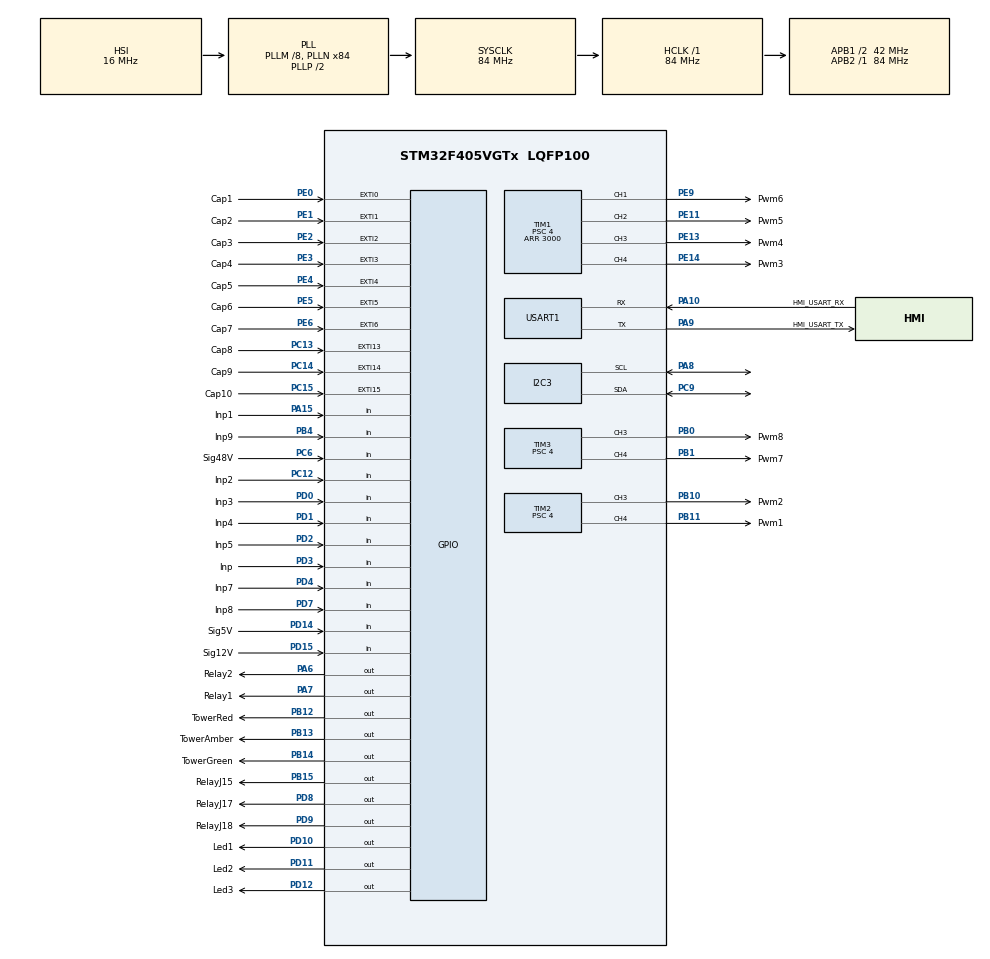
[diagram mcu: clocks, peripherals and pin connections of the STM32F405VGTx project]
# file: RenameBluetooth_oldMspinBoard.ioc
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Mcu.Family=STM32F4
Mcu.Name=STM32F405VGTx
Mcu.Package=LQFP100
NVIC.EXTI0_IRQn=true\:0\:0\:false\:false\:true\:true\:true\:true
NVIC.EXTI15_10_IRQn=true\:0\:0\:false\:false\:true\:true\:true\:true
NVIC.EXTI1_IRQn=true\:0\:0\:false\:false\:true\:true\:true\:true
NVIC.EXTI2_IRQn=true\:0\:0\:false\:false\:true\:true\:true\:true
NVIC.EXTI3_IRQn=true\:0\:0\:false\:false\:true\:true\:true\:true
NVIC.EXTI4_IRQn=true\:0\:0\:false\:false\:true\:true\:true\:true
NVIC.EXTI9_5_IRQn=true\:0\:0\:false\:false\:true\:true\:true\:true
NVIC.PriorityGroup=NVIC_PRIORITYGROUP_4
NVIC.TIM6_DAC_IRQn=true\:0\:0\:false\:false\:true\:true\:true\:true
NVIC.TIM7_IRQn=true\:0\:0\:false\:false\:true\:true\:true\:true
NVIC.USART1_IRQn=true\:0\:0\:false\:false\:true\:true\:true\:true
PA10.GPIO_Label=HMI_USART_RX
PA10.Mode=Asynchronous
PA10.Signal=USART1_RX
PA15.GPIO_Label=Inp1
PA15.Signal=GPIO_Input
PA6.GPIO_Label=Relay2
PA6.Signal=GPIO_Output
PA7.GPIO_Label=Relay1
PA7.Signal=GPIO_Output
PA8.GPIO_Pu=GPIO_PULLUP
PA8.Mode=I2C
PA8.Signal=I2C3_SCL
PA9.GPIO_Label=HMI_USART_TX
PA9.Mode=Asynchronous
PA9.Signal=USART1_TX
PB0.GPIO_Label=Pwm8
PB0.Signal=S_TIM3_CH3
PB1.GPIO_Label=Pwm7
PB1.Signal=S_TIM3_CH4
PB10.GPIO_Label=Pwm2
PB10.Signal=S_TIM2_CH3
PB11.GPIO_Label=Pwm1
PB11.Signal=S_TIM2_CH4
PB12.GPIO_Label=TowerRed
PB12.Signal=GPIO_Output
PB13.GPIO_Label=TowerAmber
PB13.Signal=GPIO_Output
PB14.GPIO_Label=TowerGreen
PB14.Signal=GPIO_Output
PB15.GPIO_Label=RelayJ15
PB15.Signal=GPIO_Output
PB4.GPIO_Label=Inp9
PB4.Signal=GPIO_Input
PC12.GPIO_Label=Inp2
PC12.Signal=GPIO_Input
PC13-ANTI_TAMP.GPIO_Label=Cap8
PC13-ANTI_TAMP.GPIO_ModeDefaultEXTI=GPIO_MODE_IT_RISING_FALLING
PC13-ANTI_TAMP.GPIO_PuPd=GPIO_PULLUP
PC13-ANTI_TAMP.Signal=GPXTI13
PC14-OSC32_IN.GPIO_Label=Cap9
PC14-OSC32_IN.GPIO_ModeDefaultEXTI=GPIO_MODE_IT_RISING_FALLING
PC14-OSC32_IN.GPIO_PuPd=GPIO_PULLUP
PC14-OSC32_IN.Signal=GPXTI14
PC15-OSC32_OUT.GPIO_Label=Cap10
PC15-OSC32_OUT.GPIO_ModeDefaultEXTI=GPIO_MODE_IT_RISING_FALLING
PC15-OSC32_OUT.GPIO_PuPd=GPIO_PULLUP
PC15-OSC32_OUT.Signal=GPXTI15
PC6.GPIO_Label=Sig48V
PC6.Signal=GPIO_Input
PC9.GPIO_Pu=GPIO_PULLUP
PC9.Mode=I2C
PC9.Signal=I2C3_SDA
PD0.GPIO_Label=Inp3
PD0.Signal=GPIO_Input
PD1.GPIO_Label=Inp4
PD1.Signal=GPIO_Input
PD10.GPIO_Label=Led1
PD10.Signal=GPIO_Output
PD11.GPIO_Label=Led2
PD11.Signal=GPIO_Output
PD12.GPIO_Label=Led3
PD12.Signal=GPIO_Output
PD14.GPIO_Label=Sig5V
PD14.Signal=GPIO_Input
PD15.GPIO_Label=Sig12V
PD15.Signal=GPIO_Input
PD2.GPIO_Label=Inp5
PD2.Signal=GPIO_Input
PD3.GPIO_Label=Inp
PD3.Signal=GPIO_Input
PD4.GPIO_Label=Inp7
PD4.Signal=GPIO_Input
PD7.GPIO_Label=Inp8
PD7.Signal=GPIO_Input
PD8.GPIO_Label=RelayJ17
PD8.Signal=GPIO_Output
PD9.GPIO_Label=RelayJ18
PD9.Signal=GPIO_Output
PE0.GPIO_Label=Cap1
PE0.GPIO_ModeDefaultEXTI=GPIO_MODE_IT_RISING_FALLING
PE0.GPIO_PuPd=GPIO_PULLUP
PE0.Signal=GPXTI0
PE1.GPIO_Label=Cap2
PE1.GPIO_ModeDefaultEXTI=GPIO_MODE_IT_RISING_FALLING
PE1.GPIO_PuPd=GPIO_PULLUP
PE1.Signal=GPXTI1
PE11.GPIO_Label=Pwm5
PE11.Signal=S_TIM1_CH2
PE13.GPIO_Label=Pwm4
PE13.Signal=S_TIM1_CH3
PE14.GPIO_Label=Pwm3
PE14.Signal=S_TIM1_CH4
PE2.GPIO_Label=Cap3
PE2.GPIO_ModeDefaultEXTI=GPIO_MODE_IT_RISING_FALLING
PE2.GPIO_PuPd=GPIO_PULLUP
PE2.Signal=GPXTI2
PE3.GPIO_Label=Cap4
PE3.GPIO_ModeDefaultEXTI=GPIO_MODE_IT_RISING_FALLING
PE3.GPIO_PuPd=GPIO_PULLUP
PE3.Signal=GPXTI3
PE4.GPIO_Label=Cap5
PE4.GPIO_ModeDefaultEXTI=GPIO_MODE_IT_RISING_FALLING
PE4.GPIO_PuPd=GPIO_PULLUP
PE4.Signal=GPXTI4
PE5.GPIO_Label=Cap6
PE5.GPIO_ModeDefaultEXTI=GPIO_MODE_IT_RISING_FALLING
PE5.GPIO_PuPd=GPIO_PULLUP
PE5.Signal=GPXTI5
PE6.GPIO_Label=Cap7
PE6.GPIO_ModeDefaultEXTI=GPIO_MODE_IT_RISING_FALLING
PE6.GPIO_PuPd=GPIO_PULLUP
PE6.Signal=GPXTI6
PE9.GPIO_Label=Pwm6
PE9.Signal=S_TIM1_CH1
ProjectManager.HeapSize=0x200
ProjectManager.StackSize=0x400
ProjectManager.TargetToolchain=STM32CubeIDE
RCC.48MHZClocksFreq_Value=42000000
RCC.AHBFreq_Value=84000000
RCC.APB1CLKDivider=RCC_HCLK_DIV2
RCC.APB1Freq_Value=42000000
RCC.APB1TimFreq_Value=84000000
RCC.APB2Freq_Value=84000000
RCC.APB2TimFreq_Value=84000000
RCC.CortexFreq_Value=84000000
RCC.HCLKFreq_Value=84000000
RCC.HSE_VALUE=25000000
RCC.HSI_VALUE=16000000
RCC.LSE_VALUE=32768
RCC.PLLM=8
RCC.PLLN=84
RCC.SYSCLKFreq_VALUE=84000000
RCC.SYSCLKSource=RCC_SYSCLKSOURCE_PLLCLK
RCC.VCOOutputFreq_Value=168000000
SH.S_TIM1_CH1.0=TIM1_CH1,PWM Generation1 CH1
SH.S_TIM1_CH2.0=TIM1_CH2,PWM Generation2 CH2
SH.S_TIM1_CH3.0=TIM1_CH3,PWM Generation3 CH3
SH.S_TIM1_CH4.0=TIM1_CH4,PWM Generation4 CH4
SH.S_TIM2_CH3.0=TIM2_CH3,PWM Generation3 CH3
SH.S_TIM2_CH4.0=TIM2_CH4,PWM Generation4 CH4
SH.S_TIM3_CH3.0=TIM3_CH3,PWM Generation3 CH3
SH.S_TIM3_CH4.0=TIM3_CH4,PWM Generation4 CH4
TIM1.Channel-PWM\ Generation1\ CH1=TIM_CHANNEL_1
TIM1.Channel-PWM\ Generation2\ CH2=TIM_CHANNEL_2
TIM1.Channel-PWM\ Generation3\ CH3=TIM_CHANNEL_3
TIM1.Channel-PWM\ Generation4\ CH4=TIM_CHANNEL_4
TIM1.OCPolarity_1=TIM_OCPOLARITY_LOW
TIM1.OCPolarity_2=TIM_OCPOLARITY_LOW
TIM1.OCPolarity_3=TIM_OCPOLARITY_LOW
TIM1.OCPolarity_4=TIM_OCPOLARITY_LOW
TIM1.Period=3000
TIM1.Prescaler=4
TIM2.Channel-PWM\ Generation3\ CH3=TIM_CHANNEL_3
TIM2.Channel-PWM\ Generation4\ CH4=TIM_CHANNEL_4
TIM2.OCPolarity_3=TIM_OCPOLARITY_LOW
TIM2.OCPolarity_4=TIM_OCPOLARITY_LOW
TIM2.Period=3000
TIM2.Prescaler=4
TIM3.Channel-PWM\ Generation3\ CH3=TIM_CHANNEL_3
TIM3.Channel-PWM\ Generation4\ CH4=TIM_CHANNEL_4
TIM3.OCPolarity_3=TIM_OCPOLARITY_LOW
TIM3.OCPolarity_4=TIM_OCPOLARITY_LOW
TIM3.Period=3000
TIM3.Prescaler=4
TIM6.Period=840
TIM6.Prescaler=9999
TIM7.Period=8400
TIM7.Prescaler=9999
USART1.VirtualMode=VM_ASYNC
VP_TIM6_VS_ClockSourceINT.Mode=Enable_Timer
VP_TIM7_VS_ClockSourceINT.Mode=Enable_Timer
board=BLOWCARD5-1

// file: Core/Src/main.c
/* USER CODE BEGIN Header */
/**
  ******************************************************************************
  * @file           : main.c
  * @brief          : Main program body
  ******************************************************************************
  * @attention
  *
  * Copyright (c) 2023 STMicroelectronics.
  * All rights reserved.
  *
  * This software is licensed under terms that can be found in the LICENSE file
  * in the root directory of this software component.
  * If no LICENSE file comes with this software, it is provided AS-IS.
  *
  ******************************************************************************
  */
/* USER CODE END Header */
#include "main.h"

/* USER CODE BEGIN Includes */
#include "stdio.h"
/* USER CODE END Includes */

I2C_HandleTypeDef hi2c3;

TIM_HandleTypeDef htim1;
TIM_HandleTypeDef htim2;
TIM_HandleTypeDef htim3;
TIM_HandleTypeDef htim6;
TIM_HandleTypeDef htim7;

UART_HandleTypeDef huart1;

/* USER CODE BEGIN PV */
char BufferTransmit[130] ;// Buffer for
char BufferRec[130];
char sendCntrlCMD = 0;
char switchOffCMD = 0;
char TXcomplete = 0;
char cmd = 0;

/* USER CODE END PV */

void SystemClock_Config(void);
static void MX_GPIO_Init(void);
static void MX_I2C3_Init(void);
static void MX_TIM1_Init(void);
static void MX_TIM2_Init(void);
static void MX_TIM3_Init(void);
static void MX_TIM6_Init(void);
static void MX_TIM7_Init(void);
static void MX_USART1_UART_Init(void);

int main(void)
{

  /* MCU Configuration--------------------------------------------------------*/

  /* Reset of all peripherals, Initializes the Flash interface and the Systick. */
  HAL_Init();

  /* Configure the system clock */
  SystemClock_Config();

  /* Initialize all configured peripherals */
  MX_GPIO_Init();
  MX_I2C3_Init();
  MX_TIM1_Init();
  MX_TIM2_Init();
  MX_TIM3_Init();
  MX_TIM6_Init();
  MX_TIM7_Init();
  MX_USART1_UART_Init();
  /* USER CODE BEGIN 2 */

  //Interrupts on HMI UART- UART1
  __HAL_UART_ENABLE_IT(&huart1,UART_IT_IDLE);//interrupt on receive buffer not empty(buffer full)
  __HAL_UART_ENABLE_IT(&huart1,UART_IT_TC );//interrupt on Transmission Complete
  HAL_UART_Receive_IT(&huart1,(uint8_t *)BufferRec,130);	 // start the receive here.

  /* USER CODE END 2 */

  /* Infinite loop */
  while (1)
  {
	  if (sendCntrlCMD){
		sprintf(BufferTransmit,"$$$");
		HAL_UART_Transmit_IT(&huart1, (uint8_t *)&BufferTransmit, 3);
		sendCntrlCMD = 0;
	  }

	  if (cmd == 1){
		sprintf(BufferTransmit,"D\n");
		HAL_UART_Transmit_IT(&huart1, (uint8_t *)&BufferTransmit, 2);
		cmd = 0;
	  }

	  if (cmd == 2){
		sprintf(BufferTransmit,"E\n");
		HAL_UART_Transmit_IT(&huart1, (uint8_t *)&BufferTransmit, 2);
		cmd = 0;
	  }

	  if (cmd == 3){
		sprintf(BufferTransmit,"SN,Flyer01\n");
		HAL_UART_Transmit_IT(&huart1, (uint8_t *)&BufferTransmit, 13);
		cmd = 0;
	}

	if (switchOffCMD){
		sprintf(BufferTransmit,"---");
		HAL_UART_Transmit_IT(&huart1, (uint8_t *)&BufferTransmit, 3);
		switchOffCMD = 0;
	}

  }
}

void SystemClock_Config(void)
{
  RCC_OscInitTypeDef RCC_OscInitStruct = {0};
  RCC_ClkInitTypeDef RCC_ClkInitStruct = {0};

  /** Configure the main internal regulator output voltage
  */
  __HAL_RCC_PWR_CLK_ENABLE();
  __HAL_PWR_VOLTAGESCALING_CONFIG(PWR_REGULATOR_VOLTAGE_SCALE1);

  /** Initializes the RCC Oscillators according to the specified parameters
  * in the RCC_OscInitTypeDef structure.
  */
  RCC_OscInitStruct.OscillatorType = RCC_OSCILLATORTYPE_HSI;
  RCC_OscInitStruct.HSIState = RCC_HSI_ON;
  RCC_OscInitStruct.HSICalibrationValue = RCC_HSICALIBRATION_DEFAULT;
  RCC_OscInitStruct.PLL.PLLState = RCC_PLL_ON;
  RCC_OscInitStruct.PLL.PLLSource = RCC_PLLSOURCE_HSI;
  RCC_OscInitStruct.PLL.PLLM = 8;
  RCC_OscInitStruct.PLL.PLLN = 84;
  RCC_OscInitStruct.PLL.PLLP = RCC_PLLP_DIV2;
  RCC_OscInitStruct.PLL.PLLQ = 4;
  if (HAL_RCC_OscConfig(&RCC_OscInitStruct) != HAL_OK)
  {
    Error_Handler();
  }

  /** Initializes the CPU, AHB and APB buses clocks
  */
  RCC_ClkInitStruct.ClockType = RCC_CLOCKTYPE_HCLK|RCC_CLOCKTYPE_SYSCLK
                              |RCC_CLOCKTYPE_PCLK1|RCC_CLOCKTYPE_PCLK2;
  RCC_ClkInitStruct.SYSCLKSource = RCC_SYSCLKSOURCE_PLLCLK;
  RCC_ClkInitStruct.AHBCLKDivider = RCC_SYSCLK_DIV1;
  RCC_ClkInitStruct.APB1CLKDivider = RCC_HCLK_DIV2;
  RCC_ClkInitStruct.APB2CLKDivider = RCC_HCLK_DIV1;

  if (HAL_RCC_ClockConfig(&RCC_ClkInitStruct, FLASH_LATENCY_2) != HAL_OK)
  {
    Error_Handler();
  }
}

static void MX_I2C3_Init(void)
{

  hi2c3.Instance = I2C3;
  hi2c3.Init.ClockSpeed = 100000;
  hi2c3.Init.DutyCycle = I2C_DUTYCYCLE_2;
  hi2c3.Init.OwnAddress1 = 0;
  hi2c3.Init.AddressingMode = I2C_ADDRESSINGMODE_7BIT;
  hi2c3.Init.DualAddressMode = I2C_DUALADDRESS_DISABLE;
  hi2c3.Init.OwnAddress2 = 0;
  hi2c3.Init.GeneralCallMode = I2C_GENERALCALL_DISABLE;
  hi2c3.Init.NoStretchMode = I2C_NOSTRETCH_DISABLE;
  if (HAL_I2C_Init(&hi2c3) != HAL_OK)
  {
    Error_Handler();
  }

}

static void MX_TIM1_Init(void)
{

  TIM_MasterConfigTypeDef sMasterConfig = {0};
  TIM_OC_InitTypeDef sConfigOC = {0};
  TIM_BreakDeadTimeConfigTypeDef sBreakDeadTimeConfig = {0};

  htim1.Instance = TIM1;
  htim1.Init.Prescaler = 4;
  htim1.Init.CounterMode = TIM_COUNTERMODE_UP;
  htim1.Init.Period = 3000;
  htim1.Init.ClockDivision = TIM_CLOCKDIVISION_DIV1;
  htim1.Init.RepetitionCounter = 0;
  htim1.Init.AutoReloadPreload = TIM_AUTORELOAD_PRELOAD_DISABLE;
  if (HAL_TIM_PWM_Init(&htim1) != HAL_OK)
  {
    Error_Handler();
  }
  sMasterConfig.MasterOutputTrigger = TIM_TRGO_RESET;
  sMasterConfig.MasterSlaveMode = TIM_MASTERSLAVEMODE_DISABLE;
  if (HAL_TIMEx_MasterConfigSynchronization(&htim1, &sMasterConfig) != HAL_OK)
  {
    Error_Handler();
  }
  sConfigOC.OCMode = TIM_OCMODE_PWM1;
  sConfigOC.Pulse = 0;
  sConfigOC.OCPolarity = TIM_OCPOLARITY_LOW;
  sConfigOC.OCNPolarity = TIM_OCNPOLARITY_HIGH;
  sConfigOC.OCFastMode = TIM_OCFAST_DISABLE;
  sConfigOC.OCIdleState = TIM_OCIDLESTATE_RESET;
  sConfigOC.OCNIdleState = TIM_OCNIDLESTATE_RESET;
  if (HAL_TIM_PWM_ConfigChannel(&htim1, &sConfigOC, TIM_CHANNEL_1) != HAL_OK)
  {
    Error_Handler();
  }
  if (HAL_TIM_PWM_ConfigChannel(&htim1, &sConfigOC, TIM_CHANNEL_2) != HAL_OK)
  {
    Error_Handler();
  }
  if (HAL_TIM_PWM_ConfigChannel(&htim1, &sConfigOC, TIM_CHANNEL_3) != HAL_OK)
  {
    Error_Handler();
  }
  if (HAL_TIM_PWM_ConfigChannel(&htim1, &sConfigOC, TIM_CHANNEL_4) != HAL_OK)
  {
    Error_Handler();
  }
  sBreakDeadTimeConfig.OffStateRunMode = TIM_OSSR_DISABLE;
  sBreakDeadTimeConfig.OffStateIDLEMode = TIM_OSSI_DISABLE;
  sBreakDeadTimeConfig.LockLevel = TIM_LOCKLEVEL_OFF;
  sBreakDeadTimeConfig.DeadTime = 0;
  sBreakDeadTimeConfig.BreakState = TIM_BREAK_DISABLE;
  sBreakDeadTimeConfig.BreakPolarity = TIM_BREAKPOLARITY_HIGH;
  sBreakDeadTimeConfig.AutomaticOutput = TIM_AUTOMATICOUTPUT_DISABLE;
  if (HAL_TIMEx_ConfigBreakDeadTime(&htim1, &sBreakDeadTimeConfig) != HAL_OK)
  {
    Error_Handler();
  }
  HAL_TIM_MspPostInit(&htim1);

}

static void MX_TIM2_Init(void)
{

  TIM_MasterConfigTypeDef sMasterConfig = {0};
  TIM_OC_InitTypeDef sConfigOC = {0};

  htim2.Instance = TIM2;
  htim2.Init.Prescaler = 4;
  htim2.Init.CounterMode = TIM_COUNTERMODE_UP;
  htim2.Init.Period = 3000;
  htim2.Init.ClockDivision = TIM_CLOCKDIVISION_DIV1;
  htim2.Init.AutoReloadPreload = TIM_AUTORELOAD_PRELOAD_DISABLE;
  if (HAL_TIM_PWM_Init(&htim2) != HAL_OK)
  {
    Error_Handler();
  }
  sMasterConfig.MasterOutputTrigger = TIM_TRGO_RESET;
  sMasterConfig.MasterSlaveMode = TIM_MASTERSLAVEMODE_DISABLE;
  if (HAL_TIMEx_MasterConfigSynchronization(&htim2, &sMasterConfig) != HAL_OK)
  {
    Error_Handler();
  }
  sConfigOC.OCMode = TIM_OCMODE_PWM1;
  sConfigOC.Pulse = 0;
  sConfigOC.OCPolarity = TIM_OCPOLARITY_LOW;
  sConfigOC.OCFastMode = TIM_OCFAST_DISABLE;
  if (HAL_TIM_PWM_ConfigChannel(&htim2, &sConfigOC, TIM_CHANNEL_3) != HAL_OK)
  {
    Error_Handler();
  }
  if (HAL_TIM_PWM_ConfigChannel(&htim2, &sConfigOC, TIM_CHANNEL_4) != HAL_OK)
  {
    Error_Handler();
  }
  HAL_TIM_MspPostInit(&htim2);

}

static void MX_TIM3_Init(void)
{

  TIM_MasterConfigTypeDef sMasterConfig = {0};
  TIM_OC_InitTypeDef sConfigOC = {0};

  htim3.Instance = TIM3;
  htim3.Init.Prescaler = 4;
  htim3.Init.CounterMode = TIM_COUNTERMODE_UP;
  htim3.Init.Period = 3000;
  htim3.Init.ClockDivision = TIM_CLOCKDIVISION_DIV1;
  htim3.Init.AutoReloadPreload = TIM_AUTORELOAD_PRELOAD_DISABLE;
  if (HAL_TIM_PWM_Init(&htim3) != HAL_OK)
  {
    Error_Handler();
  }
  sMasterConfig.MasterOutputTrigger = TIM_TRGO_RESET;
  sMasterConfig.MasterSlaveMode = TIM_MASTERSLAVEMODE_DISABLE;
  if (HAL_TIMEx_MasterConfigSynchronization(&htim3, &sMasterConfig) != HAL_OK)
  {
    Error_Handler();
  }
  sConfigOC.OCMode = TIM_OCMODE_PWM1;
  sConfigOC.Pulse = 0;
  sConfigOC.OCPolarity = TIM_OCPOLARITY_LOW;
  sConfigOC.OCFastMode = TIM_OCFAST_DISABLE;
  if (HAL_TIM_PWM_ConfigChannel(&htim3, &sConfigOC, TIM_CHANNEL_3) != HAL_OK)
  {
    Error_Handler();
  }
  if (HAL_TIM_PWM_ConfigChannel(&htim3, &sConfigOC, TIM_CHANNEL_4) != HAL_OK)
  {
    Error_Handler();
  }
  HAL_TIM_MspPostInit(&htim3);

}

static void MX_TIM6_Init(void)
{

  TIM_MasterConfigTypeDef sMasterConfig = {0};

  htim6.Instance = TIM6;
  htim6.Init.Prescaler = 9999;
  htim6.Init.CounterMode = TIM_COUNTERMODE_UP;
  htim6.Init.Period = 840;
  htim6.Init.AutoReloadPreload = TIM_AUTORELOAD_PRELOAD_DISABLE;
  if (HAL_TIM_Base_Init(&htim6) != HAL_OK)
  {
    Error_Handler();
  }
  sMasterConfig.MasterOutputTrigger = TIM_TRGO_RESET;
  sMasterConfig.MasterSlaveMode = TIM_MASTERSLAVEMODE_DISABLE;
  if (HAL_TIMEx_MasterConfigSynchronization(&htim6, &sMasterConfig) != HAL_OK)
  {
    Error_Handler();
  }

}

static void MX_TIM7_Init(void)
{

  TIM_MasterConfigTypeDef sMasterConfig = {0};

  htim7.Instance = TIM7;
  htim7.Init.Prescaler = 9999;
  htim7.Init.CounterMode = TIM_COUNTERMODE_UP;
  htim7.Init.Period = 8400;
  htim7.Init.AutoReloadPreload = TIM_AUTORELOAD_PRELOAD_DISABLE;
  if (HAL_TIM_Base_Init(&htim7) != HAL_OK)
  {
    Error_Handler();
  }
  sMasterConfig.MasterOutputTrigger = TIM_TRGO_RESET;
  sMasterConfig.MasterSlaveMode = TIM_MASTERSLAVEMODE_DISABLE;
  if (HAL_TIMEx_MasterConfigSynchronization(&htim7, &sMasterConfig) != HAL_OK)
  {
    Error_Handler();
  }

}

static void MX_USART1_UART_Init(void)
{

  huart1.Instance = USART1;
  huart1.Init.BaudRate = 115200;
  huart1.Init.WordLength = UART_WORDLENGTH_8B;
  huart1.Init.StopBits = UART_STOPBITS_1;
  huart1.Init.Parity = UART_PARITY_NONE;
  huart1.Init.Mode = UART_MODE_TX_RX;
  huart1.Init.HwFlowCtl = UART_HWCONTROL_NONE;
  huart1.Init.OverSampling = UART_OVERSAMPLING_16;
  if (HAL_UART_Init(&huart1) != HAL_OK)
  {
    Error_Handler();
  }

}

static void MX_GPIO_Init(void)
{
  GPIO_InitTypeDef GPIO_InitStruct = {0};

  /* GPIO Ports Clock Enable */
  __HAL_RCC_GPIOE_CLK_ENABLE();
  __HAL_RCC_GPIOC_CLK_ENABLE();
  __HAL_RCC_GPIOA_CLK_ENABLE();
  __HAL_RCC_GPIOB_CLK_ENABLE();
  __HAL_RCC_GPIOD_CLK_ENABLE();

  /*Configure GPIO pin Output Level */
  HAL_GPIO_WritePin(GPIOA, Relay2_Pin|Relay1_Pin, GPIO_PIN_RESET);

  /*Configure GPIO pin Output Level */
  HAL_GPIO_WritePin(GPIOB, TowerRed_Pin|TowerAmber_Pin|TowerGreen_Pin|RelayJ15_Pin, GPIO_PIN_RESET);

  /*Configure GPIO pin Output Level */
  HAL_GPIO_WritePin(GPIOD, RelayJ17_Pin|RelayJ18_Pin|Led1_Pin|Led2_Pin
                          |Led3_Pin, GPIO_PIN_RESET);

  /*Configure GPIO pins : Cap3_Pin Cap4_Pin Cap5_Pin Cap6_Pin
                           Cap7_Pin Cap1_Pin Cap2_Pin */
  GPIO_InitStruct.Pin = Cap3_Pin|Cap4_Pin|Cap5_Pin|Cap6_Pin
                          |Cap7_Pin|Cap1_Pin|Cap2_Pin;
  GPIO_InitStruct.Mode = GPIO_MODE_IT_RISING_FALLING;
  GPIO_InitStruct.Pull = GPIO_PULLUP;
  HAL_GPIO_Init(GPIOE, &GPIO_InitStruct);

  /*Configure GPIO pins : Cap8_Pin Cap9_Pin Cap10_Pin */
  GPIO_InitStruct.Pin = Cap8_Pin|Cap9_Pin|Cap10_Pin;
  GPIO_InitStruct.Mode = GPIO_MODE_IT_RISING_FALLING;
  GPIO_InitStruct.Pull = GPIO_PULLUP;
  HAL_GPIO_Init(GPIOC, &GPIO_InitStruct);

  /*Configure GPIO pins : Relay2_Pin Relay1_Pin */
  GPIO_InitStruct.Pin = Relay2_Pin|Relay1_Pin;
  GPIO_InitStruct.Mode = GPIO_MODE_OUTPUT_PP;
  GPIO_InitStruct.Pull = GPIO_NOPULL;
  GPIO_InitStruct.Speed = GPIO_SPEED_FREQ_LOW;
  HAL_GPIO_Init(GPIOA, &GPIO_InitStruct);

  /*Configure GPIO pins : TowerRed_Pin TowerAmber_Pin TowerGreen_Pin RelayJ15_Pin */
  GPIO_InitStruct.Pin = TowerRed_Pin|TowerAmber_Pin|TowerGreen_Pin|RelayJ15_Pin;
  GPIO_InitStruct.Mode = GPIO_MODE_OUTPUT_PP;
  GPIO_InitStruct.Pull = GPIO_NOPULL;
  GPIO_InitStruct.Speed = GPIO_SPEED_FREQ_LOW;
  HAL_GPIO_Init(GPIOB, &GPIO_InitStruct);

  /*Configure GPIO pins : RelayJ17_Pin RelayJ18_Pin Led1_Pin Led2_Pin
                           Led3_Pin */
  GPIO_InitStruct.Pin = RelayJ17_Pin|RelayJ18_Pin|Led1_Pin|Led2_Pin
                          |Led3_Pin;
  GPIO_InitStruct.Mode = GPIO_MODE_OUTPUT_PP;
  GPIO_InitStruct.Pull = GPIO_NOPULL;
  GPIO_InitStruct.Speed = GPIO_SPEED_FREQ_LOW;
  HAL_GPIO_Init(GPIOD, &GPIO_InitStruct);

  /*Configure GPIO pins : Sig5V_Pin Sig12V_Pin Inp3_Pin Inp4_Pin
                           Inp5_Pin Inp_Pin Inp7_Pin Inp8_Pin */
  GPIO_InitStruct.Pin = Sig5V_Pin|Sig12V_Pin|Inp3_Pin|Inp4_Pin
                          |Inp5_Pin|Inp_Pin|Inp7_Pin|Inp8_Pin;
  GPIO_InitStruct.Mode = GPIO_MODE_INPUT;
  GPIO_InitStruct.Pull = GPIO_NOPULL;
  HAL_GPIO_Init(GPIOD, &GPIO_InitStruct);

  /*Configure GPIO pins : Sig48V_Pin Inp2_Pin */
  GPIO_InitStruct.Pin = Sig48V_Pin|Inp2_Pin;
  GPIO_InitStruct.Mode = GPIO_MODE_INPUT;
  GPIO_InitStruct.Pull = GPIO_NOPULL;
  HAL_GPIO_Init(GPIOC, &GPIO_InitStruct);

  /*Configure GPIO pin : Inp1_Pin */
  GPIO_InitStruct.Pin = Inp1_Pin;
  GPIO_InitStruct.Mode = GPIO_MODE_INPUT;
  GPIO_InitStruct.Pull = GPIO_NOPULL;
  HAL_GPIO_Init(Inp1_GPIO_Port, &GPIO_InitStruct);

  /*Configure GPIO pin : Inp9_Pin */
  GPIO_InitStruct.Pin = Inp9_Pin;
  GPIO_InitStruct.Mode = GPIO_MODE_INPUT;
  GPIO_InitStruct.Pull = GPIO_NOPULL;
  HAL_GPIO_Init(Inp9_GPIO_Port, &GPIO_InitStruct);

  /* EXTI interrupt init*/
  HAL_NVIC_SetPriority(EXTI0_IRQn, 0, 0);
  HAL_NVIC_EnableIRQ(EXTI0_IRQn);

  HAL_NVIC_SetPriority(EXTI1_IRQn, 0, 0);
  HAL_NVIC_EnableIRQ(EXTI1_IRQn);

  HAL_NVIC_SetPriority(EXTI2_IRQn, 0, 0);
  HAL_NVIC_EnableIRQ(EXTI2_IRQn);

  HAL_NVIC_SetPriority(EXTI3_IRQn, 0, 0);
  HAL_NVIC_EnableIRQ(EXTI3_IRQn);

  HAL_NVIC_SetPriority(EXTI4_IRQn, 0, 0);
  HAL_NVIC_EnableIRQ(EXTI4_IRQn);

  HAL_NVIC_SetPriority(EXTI9_5_IRQn, 0, 0);
  HAL_NVIC_EnableIRQ(EXTI9_5_IRQn);

  HAL_NVIC_SetPriority(EXTI15_10_IRQn, 0, 0);
  HAL_NVIC_EnableIRQ(EXTI15_10_IRQn);

}

void Error_Handler(void)
{
  __disable_irq();
  while (1)
  {
  }
}
